# iostr715 register map
Registers are 16-bit, access not given, no defined reset value unless marked. A register's access mark holds for its fields unless they carry their own. Addresses are absolute; registers are grouped by the start of their names; [hi:lo] are bit positions; {n}, {i} and the like mark numbered series.

## WDG
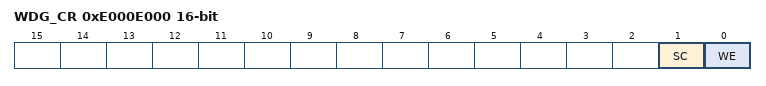
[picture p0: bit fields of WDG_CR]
0xE000E000 WDG_CR
  [1] SC, [0] WE
0xE000E004 WDG_PR
  [7:0] PR
0xE000E008 WDG_VR
0xE000E00C WDG_CNT
0xE000E010 WDG_SR
  [0] EC
0xE000E014 WDG_MR
  [0] ECM
0xE000E018 WDG_KR

## TIM0
0xE0009000 TIM0_ICAR
0xE0009004 TIM0_ICBR
0xE0009008 TIM0_OCAR
0xE000900C TIM0_OCBR
0xE0009010 TIM0_CNTR
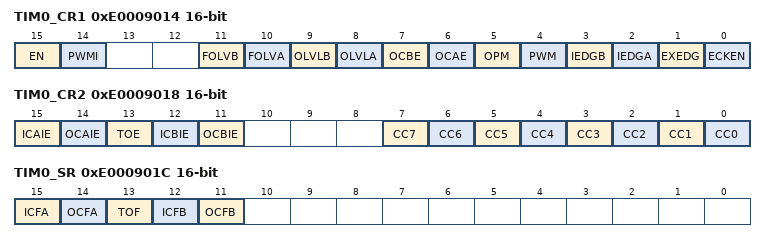
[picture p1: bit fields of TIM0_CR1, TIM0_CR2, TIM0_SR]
0xE0009014 TIM0_CR1
  [15] EN, [14] PWMI, [11] FOLVB, [10] FOLVA, [9] OLVLB, [8] OLVLA, [7] OCBE, [6] OCAE, [5] OPM, [4] PWM, [3] IEDGB, [2] IEDGA, [1] EXEDG, [0] ECKEN
0xE0009018 TIM0_CR2
  [15] ICAIE, [14] OCAIE, [13] TOE, [12] ICBIE, [11] OCBIE, [n] CC{n} (n=0..7)
0xE000901C TIM0_SR
  [15] ICFA, [14] OCFA, [13] TOF, [12] ICFB, [11] OCFB

## TIM1
0xE000A000 TIM1_ICAR
0xE000A004 TIM1_ICBR
0xE000A008 TIM1_OCAR
0xE000A00C TIM1_OCBR
0xE000A010 TIM1_CNTR
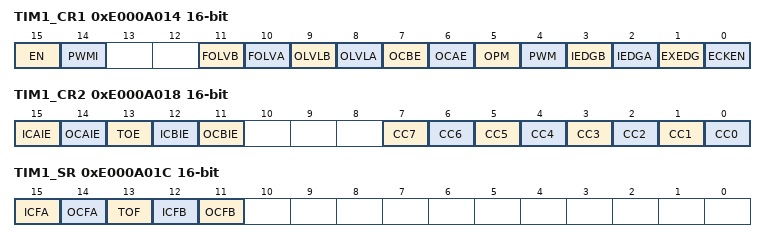
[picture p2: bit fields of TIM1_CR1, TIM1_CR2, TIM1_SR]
0xE000A014 TIM1_CR1
  [15] EN, [14] PWMI, [11] FOLVB, [10] FOLVA, [9] OLVLB, [8] OLVLA, [7] OCBE, [6] OCAE, [5] OPM, [4] PWM, [3] IEDGB, [2] IEDGA, [1] EXEDG, [0] ECKEN
0xE000A018 TIM1_CR2
  [15] ICAIE, [14] OCAIE, [13] TOE, [12] ICBIE, [11] OCBIE, [n] CC{n} (n=0..7)
0xE000A01C TIM1_SR
  [15] ICFA, [14] OCFA, [13] TOF, [12] ICFB, [11] OCFB

## TIM2
0xE000B000 TIM2_ICAR
0xE000B004 TIM2_ICBR
0xE000B008 TIM2_OCAR
0xE000B00C TIM2_OCBR
0xE000B010 TIM2_CNTR
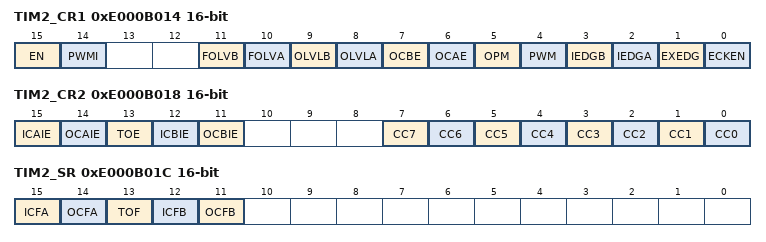
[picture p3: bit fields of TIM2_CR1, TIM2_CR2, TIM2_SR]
0xE000B014 TIM2_CR1
  [15] EN, [14] PWMI, [11] FOLVB, [10] FOLVA, [9] OLVLB, [8] OLVLA, [7] OCBE, [6] OCAE, [5] OPM, [4] PWM, [3] IEDGB, [2] IEDGA, [1] EXEDG, [0] ECKEN
0xE000B018 TIM2_CR2
  [15] ICAIE, [14] OCAIE, [13] TOE, [12] ICBIE, [11] OCBIE, [n] CC{n} (n=0..7)
0xE000B01C TIM2_SR
  [15] ICFA, [14] OCFA, [13] TOF, [12] ICFB, [11] OCFB

## TIM3
0xE000C000 TIM3_ICAR
0xE000C004 TIM3_ICBR
0xE000C008 TIM3_OCAR
0xE000C00C TIM3_OCBR
0xE000C010 TIM3_CNTR
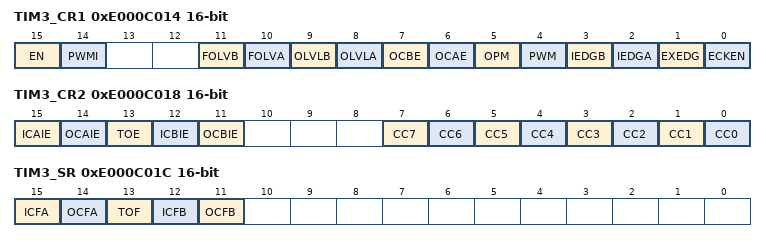
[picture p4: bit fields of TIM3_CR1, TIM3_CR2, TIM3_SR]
0xE000C014 TIM3_CR1
  [15] EN, [14] PWMI, [11] FOLVB, [10] FOLVA, [9] OLVLB, [8] OLVLA, [7] OCBE, [6] OCAE, [5] OPM, [4] PWM, [3] IEDGB, [2] IEDGA, [1] EXEDG, [0] ECKEN
0xE000C018 TIM3_CR2
  [15] ICAIE, [14] OCAIE, [13] TOE, [12] ICBIE, [11] OCBIE, [n] CC{n} (n=0..7)
0xE000C01C TIM3_SR
  [15] ICFA, [14] OCFA, [13] TOF, [12] ICFB, [11] OCFB

## I2C0
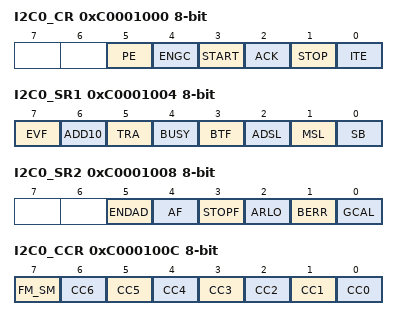
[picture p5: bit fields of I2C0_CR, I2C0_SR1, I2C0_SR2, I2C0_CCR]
0xC0001000 I2C0_CR 8-bit
  [5] PE, [4] ENGC, [3] START, [2] ACK, [1] STOP, [0] ITE
0xC0001004 I2C0_SR1 8-bit
  [7] EVF, [6] ADD10, [5] TRA, [4] BUSY, [3] BTF, [2] ADSL, [1] MSL, [0] SB
0xC0001008 I2C0_SR2 8-bit
  [5] ENDAD, [4] AF, [3] STOPF, [2] ARLO, [1] BERR, [0] GCAL
0xC000100C I2C0_CCR 8-bit
  [7] FM_SM, [n] CC{n} (n=0..6)
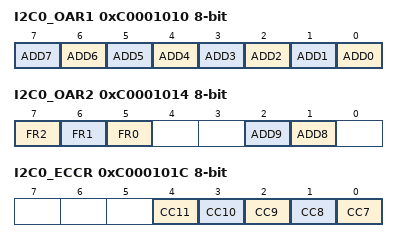
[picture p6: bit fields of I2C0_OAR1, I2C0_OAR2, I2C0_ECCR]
0xC0001010 I2C0_OAR1 8-bit
  [n] ADD{n} (n=0..7)
0xC0001014 I2C0_OAR2 8-bit
  [7] FR2, [6] FR1, [5] FR0, [2] ADD9, [1] ADD8
0xC0001018 I2C0_DR 8-bit
0xC000101C I2C0_ECCR 8-bit
  [n-7] CC{n} (n=7..11)

## I2C1
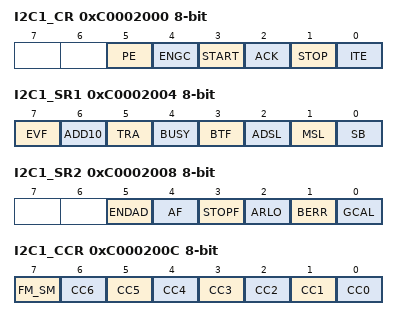
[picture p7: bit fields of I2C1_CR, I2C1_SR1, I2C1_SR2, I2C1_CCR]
0xC0002000 I2C1_CR 8-bit
  [5] PE, [4] ENGC, [3] START, [2] ACK, [1] STOP, [0] ITE
0xC0002004 I2C1_SR1 8-bit
  [7] EVF, [6] ADD10, [5] TRA, [4] BUSY, [3] BTF, [2] ADSL, [1] MSL, [0] SB
0xC0002008 I2C1_SR2 8-bit
  [5] ENDAD, [4] AF, [3] STOPF, [2] ARLO, [1] BERR, [0] GCAL
0xC000200C I2C1_CCR 8-bit
  [7] FM_SM, [n] CC{n} (n=0..6)
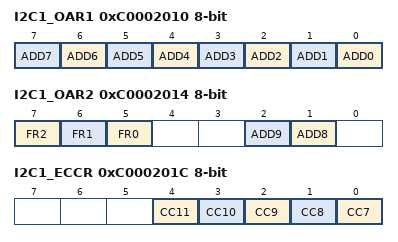
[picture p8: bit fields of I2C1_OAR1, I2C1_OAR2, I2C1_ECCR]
0xC0002010 I2C1_OAR1 8-bit
  [n] ADD{n} (n=0..7)
0xC0002014 I2C1_OAR2 8-bit
  [7] FR2, [6] FR1, [5] FR0, [2] ADD9, [1] ADD8
0xC0002018 I2C1_DR 8-bit
0xC000201C I2C1_ECCR 8-bit
  [n-7] CC{n} (n=7..11)

## BSPI0
0xC000A000 BSPI0_RXR
  [15:8] RX_8BITS
0xC000A004 BSPI0_TXR
  [15:8] TX_8BITS
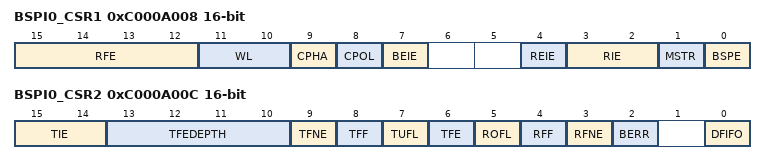
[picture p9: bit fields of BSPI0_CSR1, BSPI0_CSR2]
0xC000A008 BSPI0_CSR1
  [15:12] RFE, [11:10] WL, [9] CPHA, [8] CPOL, [7] BEIE, [4] REIE, [3:2] RIE, [1] MSTR, [0] BSPE
0xC000A00C BSPI0_CSR2
  [15:14] TIE, [13:10] TFEDEPTH, [9] TFNE, [8] TFF, [7] TUFL, [6] TFE, [5] ROFL, [4] RFF, [3] RFNE, [2] BERR, [0] DFIFO
0xC000A010 BSPI0_CLK 8-bit
